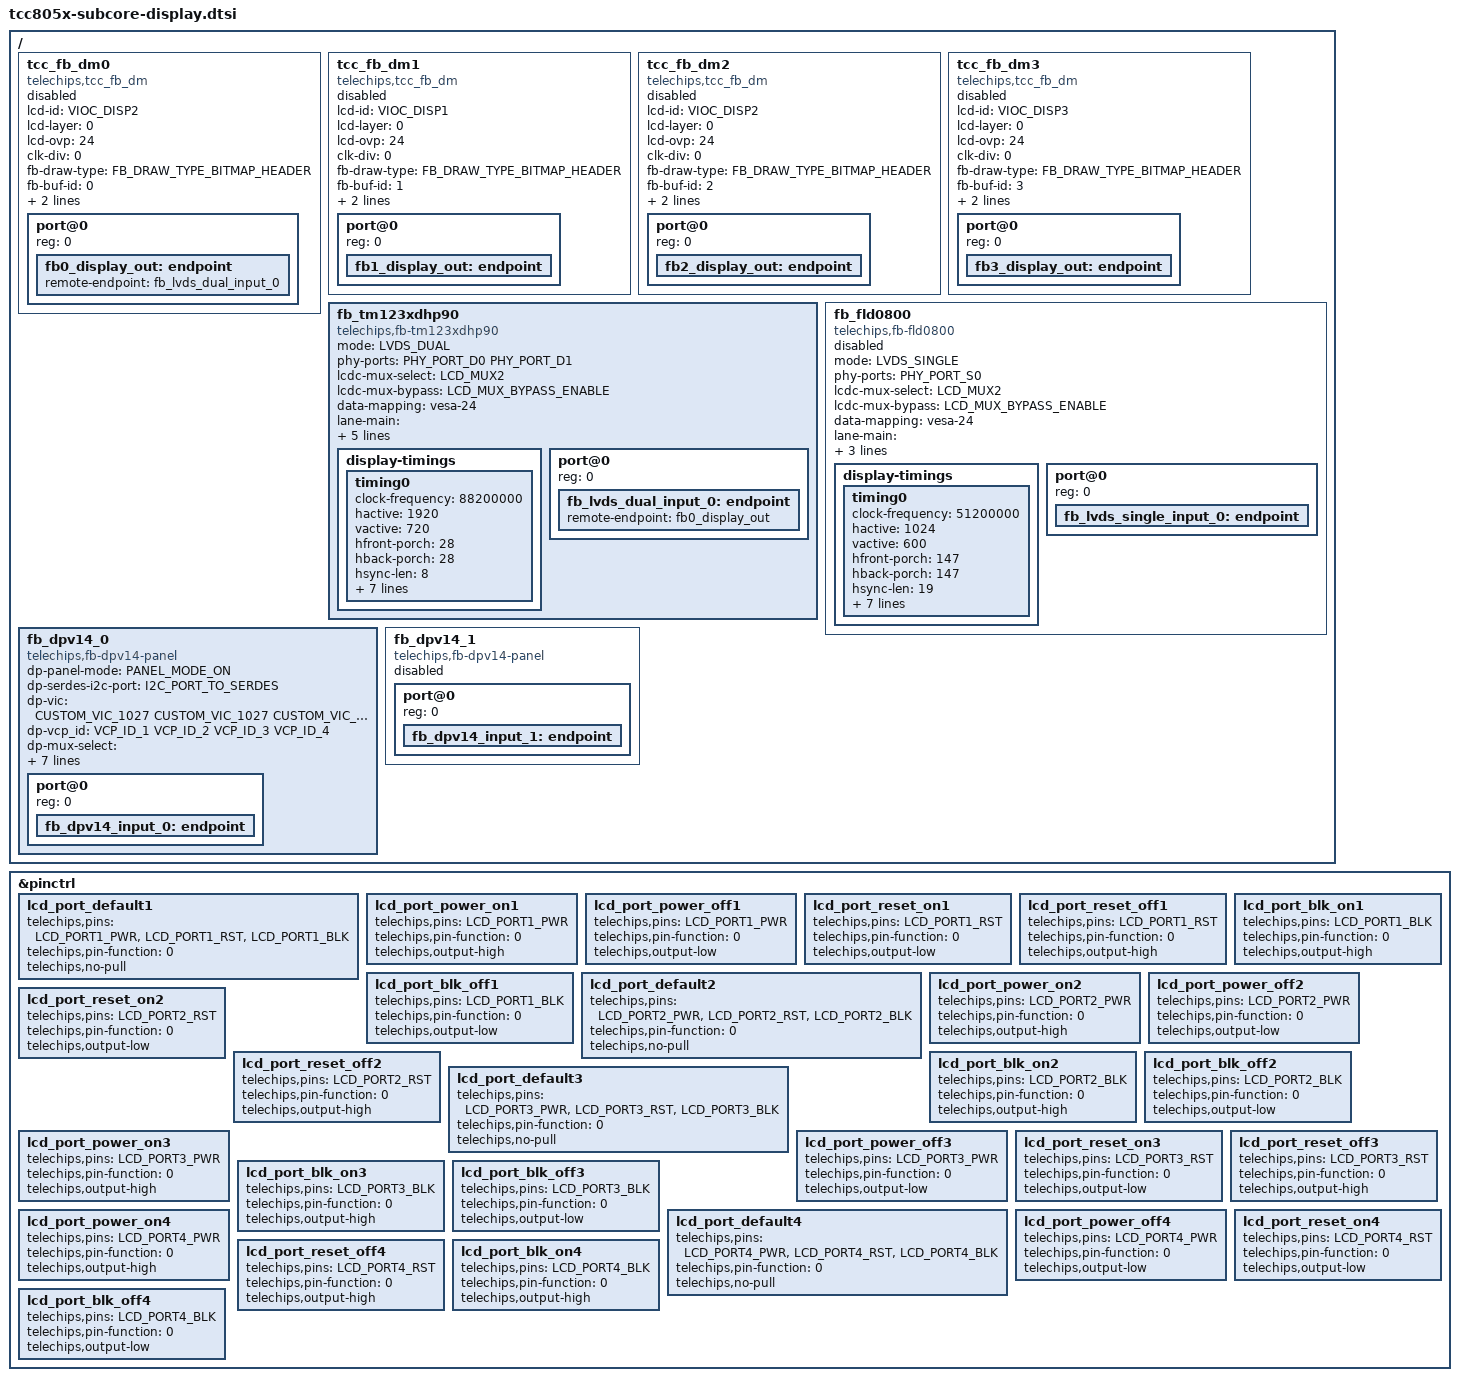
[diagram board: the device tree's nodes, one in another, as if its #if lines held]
#include <dt-bindings/display/tcc805x-vioc.h>
#include <dt-bindings/display/tcc805x-fb_dm_display.h>

&pinctrl {
	/* LCD POWER PORT 1 */
	#if defined(LCD_PORT1_PWR) && defined(LCD_PORT1_RST) && \
	defined(LCD_PORT1_BLK)
	lcd_port_default1: lcd_port_default1 {
		telechips,pins = LCD_PORT1_PWR, LCD_PORT1_RST, LCD_PORT1_BLK;
		telechips,pin-function = <0>;
		telechips,no-pull;
	};
	lcd_port_power_on1: lcd_port_power_on1 {
		telechips,pins = LCD_PORT1_PWR;
		telechips,pin-function = <0>;
		telechips,output-high;
	};
	lcd_port_power_off1: lcd_port_power_off1 {
		telechips,pins = LCD_PORT1_PWR;
		telechips,pin-function = <0>;
		telechips,output-low;
	};
	lcd_port_reset_on1: lcd_port_reset_on1 {
		telechips,pins = LCD_PORT1_RST;
		telechips,pin-function = <0>;
		telechips,output-low;
	};
	lcd_port_reset_off1: lcd_port_reset_off1 {
		telechips,pins = LCD_PORT1_RST;
		telechips,pin-function = <0>;
		telechips,output-high;
	};
	lcd_port_blk_on1: lcd_port_blk_on1 {
		telechips,pins = LCD_PORT1_BLK;
		telechips,pin-function = <0>;
		telechips,output-high;
	};
	lcd_port_blk_off1: lcd_port_blk_off1 {
		telechips,pins = LCD_PORT1_BLK;
		telechips,pin-function = <0>;
		telechips,output-low;
	};
	#endif

	/* LCD POWER PORT 2 */
	#if defined(LCD_PORT2_PWR) && defined(LCD_PORT2_RST) && \
	defined(LCD_PORT2_BLK)
	lcd_port_default2: lcd_port_default2 {
		telechips,pins = LCD_PORT2_PWR, LCD_PORT2_RST, LCD_PORT2_BLK;
		telechips,pin-function = <0>;
		telechips,no-pull;
	};
	lcd_port_power_on2: lcd_port_power_on2 {
		telechips,pins = LCD_PORT2_PWR;
		telechips,pin-function = <0>;
		telechips,output-high;
	};
	lcd_port_power_off2: lcd_port_power_off2 {
		telechips,pins = LCD_PORT2_PWR;
		telechips,pin-function = <0>;
		telechips,output-low;
	};
	lcd_port_reset_on2: lcd_port_reset_on2 {
		telechips,pins = LCD_PORT2_RST;
		telechips,pin-function = <0>;
		telechips,output-low;
	};
	lcd_port_reset_off2: lcd_port_reset_off2 {
		telechips,pins = LCD_PORT2_RST;
		telechips,pin-function = <0>;
		telechips,output-high;
	};
	lcd_port_blk_on2: lcd_port_blk_on2 {
		telechips,pins = LCD_PORT2_BLK;
		telechips,pin-function = <0>;
		telechips,output-high;
	};
	lcd_port_blk_off2: lcd_port_blk_off2 {
		telechips,pins = LCD_PORT2_BLK;
		telechips,pin-function = <0>;
		telechips,output-low;
	};
	#endif

	/* LCD POWER PORT 3 */
	#if defined(LCD_PORT3_PWR) && defined(LCD_PORT3_RST) && \
	defined(LCD_PORT3_BLK)
	lcd_port_default3: lcd_port_default3 {
		telechips,pins = LCD_PORT3_PWR, LCD_PORT3_RST, LCD_PORT3_BLK;
		telechips,pin-function = <0>;
		telechips,no-pull;
	};
	/* LVDS power on */
	lcd_port_power_on3: lcd_port_power_on3 {
		telechips,pins = LCD_PORT3_PWR;
		telechips,pin-function = <0>;
		telechips,output-high;
	};
	lcd_port_power_off3: lcd_port_power_off3 {
		telechips,pins = LCD_PORT3_PWR;
		telechips,pin-function = <0>;
		telechips,output-low;
	};
	lcd_port_reset_on3: lcd_port_reset_on3 {
		telechips,pins = LCD_PORT3_RST;
		telechips,pin-function = <0>;
		telechips,output-low;
	};
	lcd_port_reset_off3: lcd_port_reset_off3 {
		telechips,pins = LCD_PORT3_RST;
		telechips,pin-function = <0>;
		telechips,output-high;
	};
	lcd_port_blk_on3: lcd_port_blk_on3 {
		telechips,pins = LCD_PORT3_BLK;
		telechips,pin-function = <0>;
		telechips,output-high;
	};
	lcd_port_blk_off3: lcd_port_blk_off3 {
		telechips,pins = LCD_PORT3_BLK;
		telechips,pin-function = <0>;
		telechips,output-low;
	};
	#endif

	/* LCD POWER PORT 4 */
	#if defined(LCD_PORT4_PWR) && defined(LCD_PORT4_RST) && defined(LCD_PORT4_BLK)
	lcd_port_default4: lcd_port_default4 {
		telechips,pins = LCD_PORT4_PWR, LCD_PORT4_RST, LCD_PORT4_BLK;
		telechips,pin-function = <0>;
		telechips,no-pull;
	};
	lcd_port_power_on4: lcd_port_power_on4 {
		telechips,pins = LCD_PORT4_PWR;
		telechips,pin-function = <0>;
		telechips,output-high;
	};
	lcd_port_power_off4: lcd_port_power_off4 {
		telechips,pins = LCD_PORT4_PWR;
		telechips,pin-function = <0>;
		telechips,output-low;
	};
	lcd_port_reset_on4: lcd_port_reset_on4 {
		telechips,pins = LCD_PORT4_RST;
		telechips,pin-function = <0>;
		telechips,output-low;
	};
	lcd_port_reset_off4: lcd_port_reset_off4 {
		telechips,pins = LCD_PORT4_RST;
		telechips,pin-function = <0>;
		telechips,output-high;
	};
	lcd_port_blk_on4: lcd_port_blk_on4 {
		telechips,pins = LCD_PORT4_BLK;
		telechips,pin-function = <0>;
		telechips,output-high;
	};
	lcd_port_blk_off4: lcd_port_blk_off4 {
		telechips,pins = LCD_PORT4_BLK;
		telechips,pin-function = <0>;
		telechips,output-low;
	};
	#endif
};

/ {
	tcc_fb_dm0: tcc_fb_dm0{
		#address-cells = <1>;
		#size-cells = <0>;
		compatible = "telechips,tcc_fb_dm";
		status = "disabled";

		/* clocks = <&clk_peri PERI_LCD0>; */
		lcd-id = <VIOC_DISP2>;
		lcd-layer = <0>;
		lcd-ovp = <24>;
		clk-div = <0>; /* unused for now */
		fb-draw-type = <FB_DRAW_TYPE_BITMAP_HEADER>;
		fb-buf-id = <0>;
		fb-buf-addr = <0x4A800000>;
		bpix = <TCC_VIDEO_BPP32>;

		port@0 {
			reg = <0>;
			fb0_display_out: endpoint {
				remote-endpoint = <&fb_lvds_dual_input_0>;
			};
		};
	};

	tcc_fb_dm1: tcc_fb_dm1{
		#address-cells = <1>;
		#size-cells = <0>;
		compatible = "telechips,tcc_fb_dm";
		status = "disabled";

		/* clocks = <&clk_peri PERI_LCD0>; */
		lcd-id = <VIOC_DISP1>;
		lcd-layer = <0>;
		lcd-ovp = <24>;
		clk-div = <0>; /* unused for now */
		fb-draw-type = <FB_DRAW_TYPE_BITMAP_HEADER>;
		fb-buf-id = <1>;
		fb-buf-addr = <0x4B000000>;
		bpix = <TCC_VIDEO_BPP32>;

		port@0 {
			reg = <0>;
			fb1_display_out: endpoint {
			};
		};
	};

	tcc_fb_dm2: tcc_fb_dm2 {
		#address-cells = <1>;
		#size-cells = <0>;
		compatible = "telechips,tcc_fb_dm";
		status = "disabled";

		/* clocks = <&clk_peri PERI_LCD0>; */
		lcd-id = <VIOC_DISP2>;
		lcd-layer = <0>;
		lcd-ovp = <24>;
		clk-div = <0>; /* unused for now */
		fb-draw-type = <FB_DRAW_TYPE_BITMAP_HEADER>;
		fb-buf-id = <2>;
		fb-buf-addr = <0x4B800000>;
		bpix = <TCC_VIDEO_BPP32>;

		port@0 {
			reg = <0>;
			fb2_display_out: endpoint {
			};
		};
	};

	tcc_fb_dm3: tcc_fb_dm3 {
		#address-cells = <1>;
		#size-cells = <0>;
		compatible = "telechips,tcc_fb_dm";
		status = "disabled";

		/* clocks = <&clk_peri PERI_LCD0>; */
		lcd-id = <VIOC_DISP3>;
		lcd-layer = <0>;
		lcd-ovp = <24>;
		clk-div = <0>; /* unused for now */
		fb-draw-type = <FB_DRAW_TYPE_BITMAP_HEADER>;
		fb-buf-id = <3>;
		fb-buf-addr = <0x4C000000>;
		bpix = <TCC_VIDEO_BPP32>;

		port@0 {
			reg = <0>;
			fb3_display_out: endpoint {
			};
		};
	};

	fb_tm123xdhp90: fb_tm123xdhp90 {
		#address-cells = <1>;
		#size-cells = <0>;
		compatible = "telechips,fb-tm123xdhp90";
		status = "okay";

		mode = <LVDS_DUAL>;   /* 0: single 1: dual */
		phy-ports = <PHY_PORT_D0 PHY_PORT_D1>; /*port main, port sub*/
		lcdc-mux-select = <LCD_MUX2>;
		lcdc-mux-bypass = <LCD_MUX_BYPASS_ENABLE>; /* 0: use sdm|trvc path, 1: mux bypass */
		data-mapping = "vesa-24";
		lane-main = <DATA3_LANE CLK_LANE DATA2_LANE DATA1_LANE DATA0_LANE>;
		lane-sub = <DATA0_LANE DATA1_LANE DATA2_LANE CLK_LANE DATA3_LANE>;
		vcm = <1200>;
		vsw = <500>;

		display-timings {
			timing0 {
				clock-frequency = <88200000>;
				hactive = <1920>;
				vactive = <720>;
				hfront-porch = <28>;
				hback-porch = <28>;
				hsync-len = <8>;
				hsync-active = <0>;
				vback-porch = <10>;
				vfront-porch = <10>;
				vsync-len = <2>;
				vsync-active = <0>;
				de-active = <1>;
				pixelclk-active = <1>;
			};
		};

		port@0 {
			reg = <0>;
			fb_lvds_dual_input_0: endpoint {
				remote-endpoint = <&fb0_display_out>;
			};
		};
	};

	fb_fld0800: fb_fld0800 {
		#address-cells = <1>;
		#size-cells = <0>;
		compatible = "telechips,fb-fld0800";
		status = "disabled";

		mode = <LVDS_SINGLE>;   /* 0: single 1: dual */
		phy-ports = <PHY_PORT_S0>; /*port main, port sub*/
		lcdc-mux-select = <LCD_MUX2>;
		lcdc-mux-bypass = <LCD_MUX_BYPASS_ENABLE>; /* 0: use sdm|trvc path, 1: mux bypass */
		data-mapping = "vesa-24";
		lane-main = <DATA0_LANE DATA1_LANE DATA2_LANE CLK_LANE DATA3_LANE>;
		vcm = <1200>;
		vsw = <400>;

		display-timings {
			timing0 {
				clock-frequency = <51200000>;
				hactive = <1024>;
				vactive = <600>;
				hfront-porch = <147>;
				hback-porch = <147>;
				hsync-len = <19>;
				hsync-active = <0>;
				vback-porch = <10>;
				vfront-porch = <25>;
				vsync-len = <2>;
				vsync-active = <0>;
				de-active = <1>;
				pixelclk-active = <1>;
			};
		};

		port@0 {
			reg = <0>;
			fb_lvds_single_input_0: endpoint {
			};
		};
	};

	fb_dpv14_0: fb_dpv14_0 {
		#address-cells = <1>;
		#size-cells = <0>;
		compatible = "telechips,fb-dpv14-panel";
		status = "okay";

		dp-panel-mode = <PANEL_MODE_ON>;
		dp-serdes-i2c-port = <I2C_PORT_TO_SERDES>; /* For PANEL_MODE_ON */
		dp-vic = <CUSTOM_VIC_1027 CUSTOM_VIC_1027 CUSTOM_VIC_1027 CUSTOM_VIC_1027>;
		dp-vcp_id = <VCP_ID_1 VCP_ID_2 VCP_ID_3 VCP_ID_4>;
		dp-mux-select = <LCD_MUX3 LCD_MUX0 LCD_MUX1 LCD_MUX2>;
		dp-phy-lane-swap = <PHY_LANE_SWAP_ON>;
		dp-sdm-bypass = <SDM_BYPASS_ENABLE>;
		dp-trvc-bypass = <TRVC_BYPASS_ENABLE>;
		dp-pixel-encoding = <PIXEL_ENCODING_RGB>;
		dp-max-lane = <PHY_LINK_LANE_4>;
		dp-max-rate = <PHY_LINK_RATE_HBR3>;

		port@0 {
			reg = <0>;
			fb_dpv14_input_0: endpoint {
			};
		};
	};

	fb_dpv14_1: fb_dpv14_1 {
		#address-cells = <1>;
		#size-cells = <0>;
		compatible = "telechips,fb-dpv14-panel";
		status = "disabled";

		port@0 {
			reg = <0>;
			fb_dpv14_input_1: endpoint {
			};
		};
	};
};
